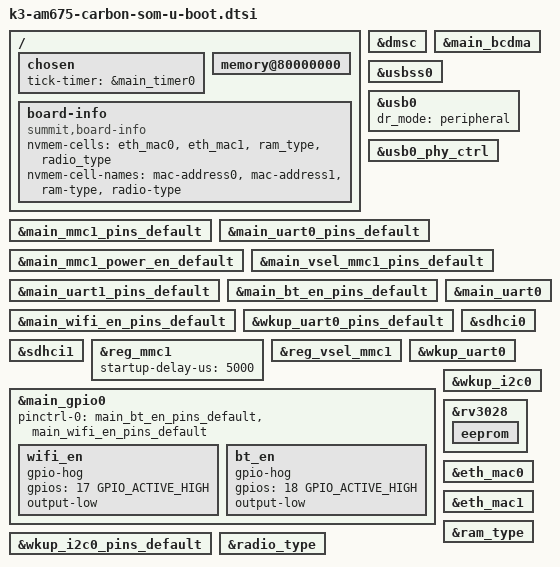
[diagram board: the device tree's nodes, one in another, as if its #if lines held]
// SPDX-License-Identifier: GPL-2.0
/*
 * Common AM67 Carbon dts file for SPLs
 * Copyright (C) 2025 Ezurio LLC
 */

#include "k3-am675-carbon-som-binman.dtsi"

/ {
	chosen {
		tick-timer = &main_timer0;
	};

	memory@80000000 {
		bootph-pre-ram;
	};

	board-info {
		compatible = "summit,board-info";
		bootph-all;

		nvmem-cells = <&eth_mac0>, <&eth_mac1>, <&ram_type>,
			<&radio_type>;
		nvmem-cell-names = "mac-address0", "mac-address1", "ram-type",
			"radio-type";
	};
};

&dmsc {
	bootph-pre-ram;
};

&main_bcdma {
	bootph-pre-ram;
};

#ifdef CONFIG_SPL_DFU
/* Required for USB DFU Boot */
&usbss0 {
	bootph-all;
};

&usb0 {
	dr_mode = "peripheral";
	bootph-all;
};

&usb0_phy_ctrl {
	bootph-all;
};
#endif

&main_mmc1_pins_default {
	bootph-all;
};

&main_uart0_pins_default {
	bootph-all;
};

&main_mmc1_power_en_default {
	bootph-all;
};

&main_vsel_mmc1_pins_default {
	bootph-all;
};

&main_uart1_pins_default {
	bootph-pre-ram;
};

&main_bt_en_pins_default {
	bootph-all;
};

&main_wifi_en_pins_default {
	bootph-all;
};

&main_uart0 {
	bootph-all;
};

&wkup_uart0_pins_default {
	bootph-pre-ram;
};

&sdhci0 {
	bootph-all;
};

&sdhci1 {
	bootph-all;
};

&reg_mmc1 {
	bootph-all;
	startup-delay-us = <5000>;
};

&reg_vsel_mmc1 {
	bootph-all;
};

&wkup_uart0 {
	bootph-pre-ram;
};

&main_gpio0 {
	bootph-all;
	pinctrl-names = "default";
	pinctrl-0 = <&main_bt_en_pins_default>, <&main_wifi_en_pins_default>;

	wifi_en {
		bootph-pre-ram;
		gpio-hog;
		gpios = <17 GPIO_ACTIVE_HIGH>;
		output-low;
	};

	bt_en {
		bootph-pre-ram;
		gpio-hog;
		gpios = <18 GPIO_ACTIVE_HIGH>;
		output-low;
	};
};

&wkup_i2c0_pins_default {
	bootph-all;
};

&wkup_i2c0 {
	bootph-all;
};

&rv3028 {
	bootph-all;

	eeprom {
		bootph-all;
	};
};

&eth_mac0 {
	bootph-all;
};

&eth_mac1 {
	bootph-all;
};

&ram_type {
	bootph-all;
};

&radio_type {
	bootph-all;
};
